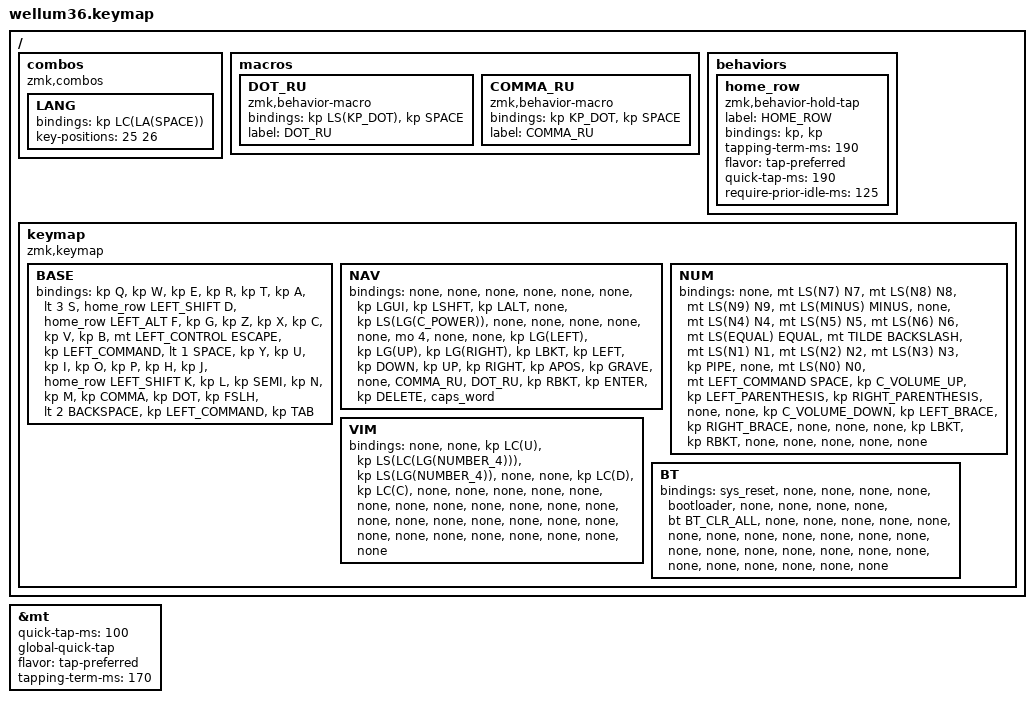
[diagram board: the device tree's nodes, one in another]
#include <behaviors.dtsi>
#include <dt-bindings/zmk/bt.h>
#include <dt-bindings/zmk/keys.h>

#define BASE 0
#define NAV  1
#define SYM  2
#define ADJ  3
#define TVP1 4
#define TVP2 5

&mt {
    quick-tap-ms = <100>;
    global-quick-tap;
    flavor = "tap-preferred";
    tapping-term-ms = <170>;
};

/ {
    combos {
        compatible = "zmk,combos";

        LANG {
            bindings = <&kp LC(LA(SPACE))>;
            key-positions = <25 26>;
        };
    };

    macros {
        DOT_RU: DOT_RU {
            compatible = "zmk,behavior-macro";
            #binding-cells = <0>;
            bindings = <&kp LS(KP_DOT) &kp SPACE>;
            label = "DOT_RU";
        };

        COMMA_RU: COMMA_RU {
            compatible = "zmk,behavior-macro";
            #binding-cells = <0>;
            bindings = <&kp KP_DOT &kp SPACE>;
            label = "COMMA_RU";
        };
    };

    behaviors {
        home_row: home_row {
            compatible = "zmk,behavior-hold-tap";
            label = "HOME_ROW";
            bindings = <&kp>, <&kp>;

            #binding-cells = <2>;
            tapping-term-ms = <190>;
            flavor = "tap-preferred";
            quick-tap-ms = <190>;
            require-prior-idle-ms = <125>;
        };
    };

    keymap {
        compatible = "zmk,keymap";

        // ▄▄▄▄▄▄▄▄▄▄▄▄▄▄▄▄▄▄▄▄▄▄▄▄▄▄▄▄▄▄▄▄▄▄▄▄▄▄▄▄▄▄▄▄▄▄▄▄▄▄▄▄▄▄▄▄▄▄▄▄▄▄▄▄▄▄▄▄▄▄▄▄▄▄▄▄▄▄▄▄▄▄▄▄▄▄▄▄▄▄▄▄▄▄▄▄▄▄▄▄▄▄▄▄▄▄▄▄▄▄▄▄▄▄▄▄▄▄▄▄▄▄▄▄▄▄▄▄▄▄▄▄▄▄▄▄▄▄▄▄▄▄▄▄▄▄▄▄▄

        BASE {
            // ┏━━━━━━━━━━━━━━━━━━━━━━━━━━━━━━━━━━━━━━━┓
            // ┗━━━━━━━━━━━━━━━━━━━━━━━━━━━━━━━━━━━━━━━┛
            //             ┏━━━━━━━━━━━┳━━━━━━━━━━━┳━━━━━━━━━━━┳━━━━━━━━━━━┳━━━━━━━━━━━┓   ┏━━━━━━━━━━━┳━━━━━━━━━━━┳━━━━━━━━━━━┳━━━━━━━━━━━┳━━━━━━━━━━━┓
            //             ┃     Q     ┃     W     ┃     F     ┃     P     ┃     G     ┃   ┃     J     ┃     L     ┃     U     ┃     Y     ┃     ;     ┃
            //             ┣━━━━━━━━━━━╋━━━━━━━━━━━╋━━━━━━━━━━━╋━━━━━━━━━━━╋━━━━━━━━━━━┫   ┣━━━━━━━━━━━╋━━━━━━━━━━━╋━━━━━━━━━━━╋━━━━━━━━━━━╋━━━━━━━━━━━┫
            //             ┃     A     ┃     R     ┃     S     ┃     T     ┃     D     ┃   ┃     H     ┃     N     ┃     E     ┃     I     ┃     O     ┃
            // ┏━━━━━━━━━━━╋━━━━━━━━━━━╋━━━━━━━━━━━╋━━━━━━━━━━━╋━━━━━━━━━━━╋━━━━━━━━━━━┫   ┣━━━━━━━━━━━╋━━━━━━━━━━━╋━━━━━━━━━━━╋━━━━━━━━━━━╋━━━━━━━━━━━╋━━━━━━━━━━━┓
            // ┃     Q     ┃     Z     ┃     X     ┃     C     ┃     V     ┃     B     ┃   ┃     K     ┃     M     ┃     ,     ┃     .     ┃     /     ┃     \     ┃
            // ┗━━━━━━━━━━━┻━━━━━━━━━━━┻━━━━━━━━━━━╋━━━━━━━━━━━╋━━━━━━━━━━━╋━━━━━━━━━━━┫   ┣━━━━━━━━━━━╋━━━━━━━━━━━╋━━━━━━━━━━━╋━━━━━━━━━━━┻━━━━━━━━━━━┻━━━━━━━━━━━┛
            //                                     ┃    DEL    ┃    TAB    ┃    SPC    ┃   ┃   ENTER   ┃           ┃   BSPC    ┃
            //                                     ┗━━━━━━━━━━━┻━━━━━━━━━━━┻━━━━━━━━━━━┛   ┗━━━━━━━━━━━┻━━━━━━━━━━━┻━━━━━━━━━━━┛

            bindings = <
&kp Q  &kp W  &kp E  &kp R  &kp T  &kp A  &lt 3 S  &home_row LEFT_SHIFT D  &home_row LEFT_ALT F  &kp G  &kp Z  &kp X  &kp C  &kp V  &kp B  &mt LEFT_CONTROL ESCAPE  &kp LEFT_COMMAND  &lt 1 SPACE  &kp Y  &kp U  &kp I  &kp O  &kp P  &kp H  &kp J  &home_row LEFT_SHIFT K  &kp L  &kp SEMI  &kp N  &kp M  &kp COMMA  &kp DOT  &kp FSLH  &lt 2 BACKSPACE  &kp LEFT_COMMAND  &kp TAB
            >;
        };

        NAV {
            bindings = <
&none  &none  &none  &none  &none  &none  &kp LGUI  &kp LSHFT  &kp LALT  &none  &kp LS(LG(C_POWER))  &none  &none  &none  &none  &none  &mo 4  &none  &none  &kp LG(LEFT)  &kp LG(UP)  &kp LG(RIGHT)  &kp LBKT  &kp LEFT  &kp DOWN  &kp UP  &kp RIGHT  &kp APOS  &kp GRAVE  &none  &COMMA_RU  &DOT_RU  &kp RBKT  &kp ENTER  &kp DELETE  &caps_word
            >;
        };

        NUM {
            bindings = <
&none  &mt LS(N7) N7  &mt LS(N8) N8  &mt LS(N9) N9  &mt LS(MINUS) MINUS  &none  &mt LS(N4) N4  &mt LS(N5) N5  &mt LS(N6) N6  &mt LS(EQUAL) EQUAL  &mt TILDE BACKSLASH  &mt LS(N1) N1  &mt LS(N2) N2  &mt LS(N3) N3  &kp PIPE  &none  &mt LS(N0) N0  &mt LEFT_COMMAND SPACE  &kp C_VOLUME_UP  &kp LEFT_PARENTHESIS  &kp RIGHT_PARENTHESIS  &none  &none  &kp C_VOLUME_DOWN  &kp LEFT_BRACE  &kp RIGHT_BRACE  &none  &none  &none  &kp LBKT  &kp RBKT  &none  &none  &none  &none  &none
            >;
        };

        VIM {
            bindings = <
&none  &none  &kp LC(U)  &kp LS(LC(LG(NUMBER_4)))  &kp LS(LG(NUMBER_4))  &none  &none  &kp LC(D)  &kp LC(C)  &none  &none  &none  &none  &none  &none  &none  &none  &none  &none  &none  &none  &none  &none  &none  &none  &none  &none  &none  &none  &none  &none  &none  &none  &none  &none  &none
            >;
        };

        BT {
            // ┏━━━━━━━━━━━━━━━━━━━━━━━━━━━━━━━━━━━━━━━┓
            // ┗━━━━━━━━━━━━━━━━━━━━━━━━━━━━━━━━━━━━━━━┛
            //             ┏━━━━━━━━━━━┳━━━━━━━━━━━┳━━━━━━━━━━━┳━━━━━━━━━━━┳━━━━━━━━━━━┓   ┏━━━━━━━━━━━┳━━━━━━━━━━━┳━━━━━━━━━━━┳━━━━━━━━━━━┳━━━━━━━━━━━┓
            //             ┃   RESET   ┃ BT CLEAR  ┃  OUT TOG  ┃           ┃           ┃   ┃           ┃    F7     ┃    F8     ┃    F9     ┃    F12    ┃
            //             ┣━━━━━━━━━━━╋━━━━━━━━━━━╋━━━━━━━━━━━╋━━━━━━━━━━━╋━━━━━━━━━━━┫   ┣━━━━━━━━━━━╋━━━━━━━━━━━╋━━━━━━━━━━━╋━━━━━━━━━━━╋━━━━━━━━━━━┫
            //             ┃ BOOTLOAD  ┃ BT NEXT   ┃           ┃           ┃           ┃   ┃           ┃    F4     ┃    F5     ┃    F6     ┃    F11    ┃
            // ┏━━━━━━━━━━━╋━━━━━━━━━━━╋━━━━━━━━━━━╋━━━━━━━━━━━╋━━━━━━━━━━━╋━━━━━━━━━━━┫   ┣━━━━━━━━━━━╋━━━━━━━━━━━╋━━━━━━━━━━━╋━━━━━━━━━━━╋━━━━━━━━━━━╋━━━━━━━━━━━┓
            // ┃           ┃           ┃ BT PREV   ┃           ┃           ┃           ┃   ┃           ┃    F1     ┃    F2     ┃    F3     ┃    F10    ┃           ┃
            // ┗━━━━━━━━━━━┻━━━━━━━━━━━┻━━━━━━━━━━━╋━━━━━━━━━━━╋━━━━━━━━━━━╋━━━━━━━━━━━┫   ┣━━━━━━━━━━━╋━━━━━━━━━━━╋━━━━━━━━━━━╋━━━━━━━━━━━┻━━━━━━━━━━━┻━━━━━━━━━━━┛
            //                                     ┃           ┃           ┃           ┃   ┃           ┃           ┃           ┃
            //                                     ┗━━━━━━━━━━━┻━━━━━━━━━━━┻━━━━━━━━━━━┛   ┗━━━━━━━━━━━┻━━━━━━━━━━━┻━━━━━━━━━━━┛

            bindings = <
&sys_reset  &none  &none  &none  &none  &bootloader  &none  &none  &none  &none  &bt BT_CLR_ALL  &none  &none  &none  &none  &none  &none  &none  &none  &none  &none  &none  &none  &none  &none  &none  &none  &none  &none  &none  &none  &none  &none  &none  &none  &none
            >;
        };
    };
};
